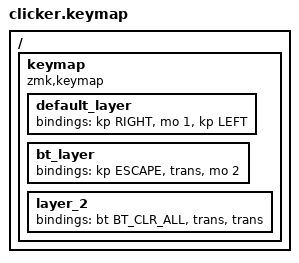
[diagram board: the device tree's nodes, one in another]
#include <behaviors.dtsi>
#include <dt-bindings/zmk/bt.h>
#include <dt-bindings/zmk/keys.h>

/ {
    keymap {
        compatible = "zmk,keymap";

        default_layer {
            bindings = <
&kp RIGHT  &mo 1  &kp LEFT
            >;
        };

        bt_layer {
            bindings = <
&kp ESCAPE  &trans  &mo 2
            >;
        };

        layer_2 {
            bindings = <
&bt BT_CLR_ALL  &trans  &trans
            >;
        };
    };
};
